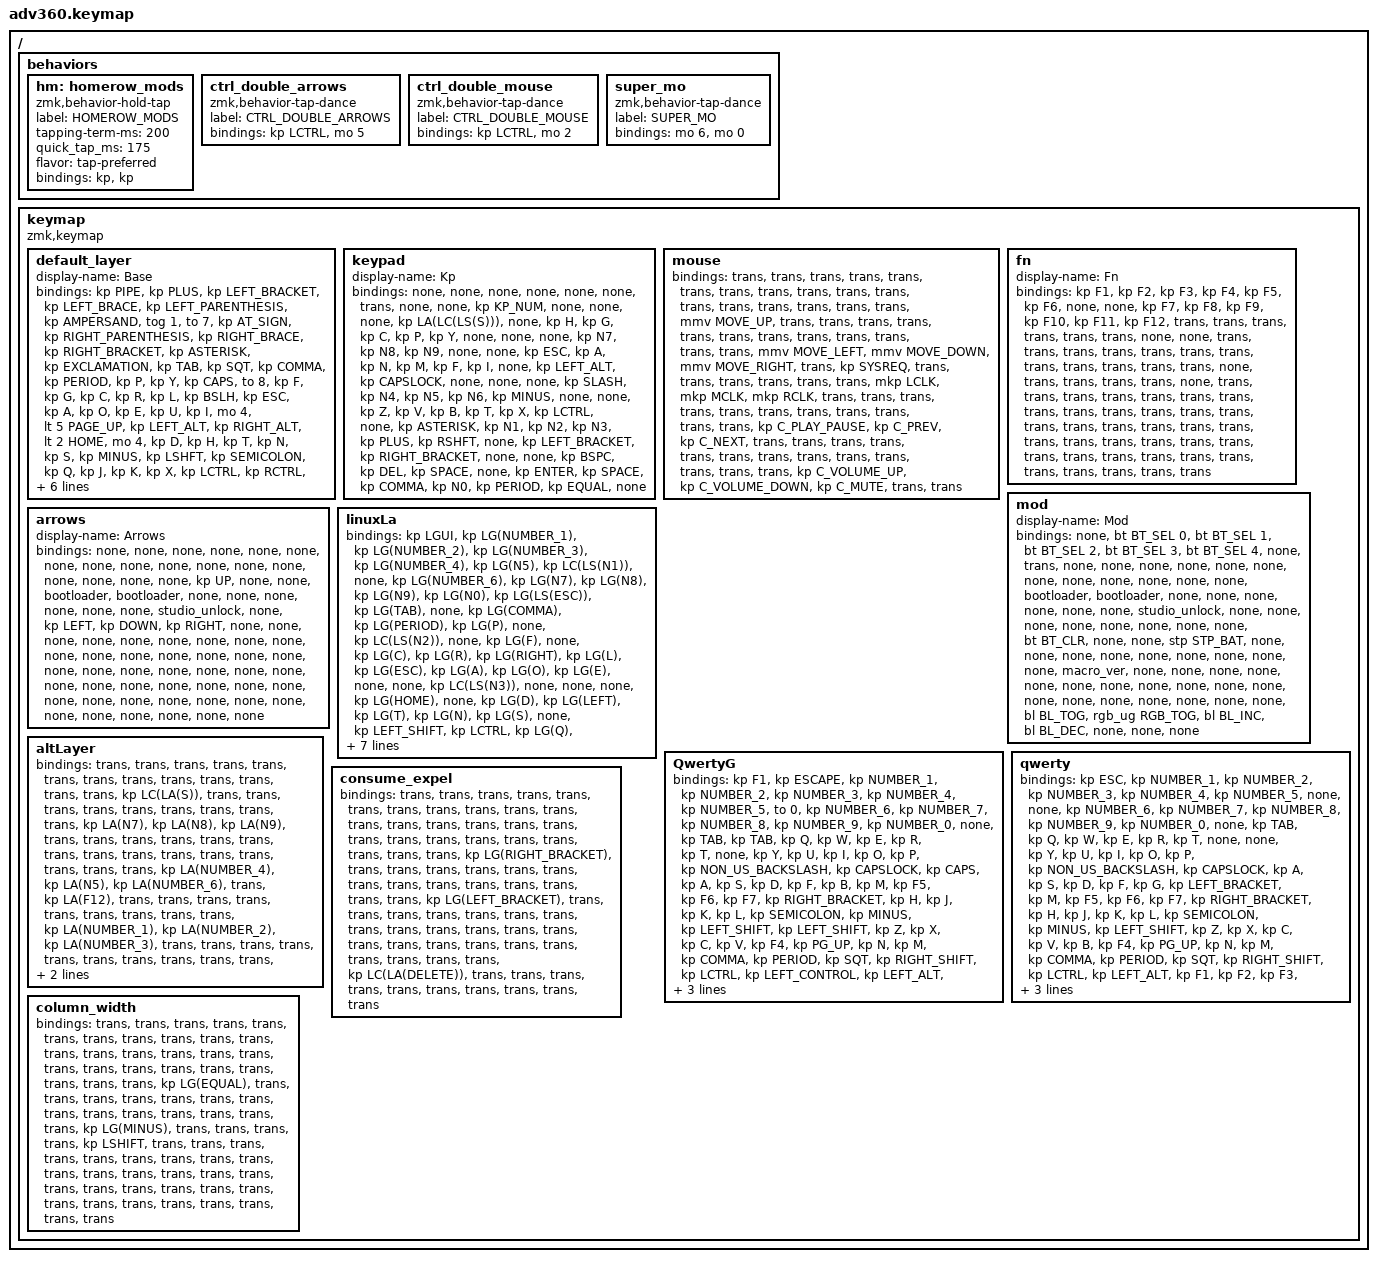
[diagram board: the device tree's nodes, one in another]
#include <dt-bindings/zmk/stp.h>
#include <behaviors.dtsi>
#include <dt-bindings/zmk/backlight.h>
#include <dt-bindings/zmk/bt.h>
#include <dt-bindings/zmk/keys.h>
#include <dt-bindings/zmk/pointing.h>
#include <dt-bindings/zmk/rgb.h>

#define ZMK_POINTING_DEFAULT_MOVE_VAL 1500

/ {
    behaviors {
        #include "macros.dtsi"
      #include "version.dtsi"

        hm: homerow_mods {
            compatible = "zmk,behavior-hold-tap";
            label = "HOMEROW_MODS";
            #binding-cells = <2>;
            tapping-term-ms = <200>;
            quick_tap_ms = <175>;
            flavor = "tap-preferred";
            bindings = <&kp>, <&kp>;
        };

        ctrl_double_arrows: ctrl_double_arrows {
            compatible = "zmk,behavior-tap-dance";
            label = "CTRL_DOUBLE_ARROWS";
            #binding-cells = <0>;
            bindings = <&kp LCTRL>, <&mo 5>;
        };

        ctrl_double_mouse: ctrl_double_mouse {
            compatible = "zmk,behavior-tap-dance";
            label = "CTRL_DOUBLE_MOUSE";
            #binding-cells = <0>;
            bindings = <&kp LCTRL>, <&mo 2>;
        };

        super_mo: super_mo {
            compatible = "zmk,behavior-tap-dance";
            label = "SUPER_MO";
            #binding-cells = <0>;
            bindings = <&mo 6>, <&mo 0>;
        };
    };

    keymap {
        compatible = "zmk,keymap";

        default_layer {
            display-name = "Base";
            bindings = <
&kp PIPE   &kp PLUS       &kp LEFT_BRACKET  &kp LEFT_BRACE  &kp LEFT_PARENTHESIS  &kp AMPERSAND  &tog 1                                                                   &to 7      &kp AT_SIGN  &kp RIGHT_PARENTHESIS  &kp RIGHT_BRACE  &kp RIGHT_BRACKET  &kp ASTERISK  &kp EXCLAMATION
&kp TAB    &kp SQT        &kp COMMA         &kp PERIOD      &kp P                 &kp Y          &kp CAPS                                                                 &to 8      &kp F        &kp G                  &kp C            &kp R              &kp L         &kp BSLH
&kp ESC    &kp A          &kp O             &kp E           &kp U                 &kp I          &mo 4     &lt 5 PAGE_UP  &kp LEFT_ALT         &kp RIGHT_ALT  &lt 2 HOME  &mo 4      &kp D        &kp H                  &kp T            &kp N              &kp S         &kp MINUS
&kp LSHFT  &kp SEMICOLON  &kp Q             &kp J           &kp K                 &kp X                                   &kp LCTRL            &kp RCTRL                             &kp B        &kp M                  &kp W            &kp V              &kp Z         &kp RSHFT
&mo 3      &kp DOLLAR     &kp GRAVE         &kp TILDE       &lt 1 PERCENT                        &kp BSPC  &kp DEL        &lt 6 PAGE_DOWN      &lt 9 END      &kp ENTER   &kp SPACE               &kp HASH               &kp CARET        &kp SLASH          &kp EQUAL     &mo 3
            >;
        };

        keypad {
            display-name = "Kp";
            bindings = <
&none    &none             &none              &none  &none  &none  &trans                                                      &none      &none         &kp KP_NUM  &none   &none       &none      &kp LA(LC(LS(S)))
&none    &kp H             &kp G              &kp C  &kp P  &kp Y  &none                                                       &none      &none         &kp N7      &kp N8  &kp N9      &none      &none
&kp ESC  &kp A             &kp N              &kp M  &kp F  &kp I  &none     &kp LEFT_ALT  &kp CAPSLOCK      &none  &none      &none      &kp SLASH     &kp N4      &kp N5  &kp N6      &kp MINUS  &none
&none    &kp Z             &kp V              &kp B  &kp T  &kp X                          &kp LCTRL         &none                        &kp ASTERISK  &kp N1      &kp N2  &kp N3      &kp PLUS   &kp RSHFT
&none    &kp LEFT_BRACKET  &kp RIGHT_BRACKET  &none  &none         &kp BSPC  &kp DEL       &kp SPACE         &none  &kp ENTER  &kp SPACE                &kp COMMA   &kp N0  &kp PERIOD  &kp EQUAL  &none
            >;
        };

        mouse {
            bindings = <
&trans  &trans  &trans          &trans          &trans           &trans  &trans                                          &trans  &trans  &trans            &trans             &trans      &trans  &trans
&trans  &trans  &trans          &mmv MOVE_UP    &trans           &trans  &trans                                          &trans  &trans  &trans            &trans             &trans      &trans  &trans
&trans  &trans  &mmv MOVE_LEFT  &mmv MOVE_DOWN  &mmv MOVE_RIGHT  &trans  &kp SYSREQ  &trans  &trans      &trans  &trans  &trans  &trans  &mkp LCLK         &mkp MCLK          &mkp RCLK   &trans  &trans
&trans  &trans  &trans          &trans          &trans           &trans                      &trans      &trans                  &trans  &kp C_PLAY_PAUSE  &kp C_PREV         &kp C_NEXT  &trans  &trans
&trans  &trans  &trans          &trans          &trans                   &trans      &trans  &trans      &trans  &trans  &trans          &kp C_VOLUME_UP   &kp C_VOLUME_DOWN  &kp C_MUTE  &trans  &trans
            >;
        };

        fn {
            display-name = "Fn";
            bindings = <
&kp F1  &kp F2  &kp F3  &kp F4  &kp F5  &kp F6  &none                                       &none   &kp F7  &kp F8  &kp F9  &kp F10  &kp F11  &kp F12
&trans  &trans  &trans  &trans  &trans  &trans  &none                                       &none   &trans  &trans  &trans  &trans   &trans   &trans
&trans  &trans  &trans  &trans  &trans  &trans  &none   &trans  &trans      &trans  &trans  &none   &trans  &trans  &trans  &trans   &trans   &trans
&trans  &trans  &trans  &trans  &trans  &trans                  &trans      &trans                  &trans  &trans  &trans  &trans   &trans   &trans
&trans  &trans  &trans  &trans  &trans          &trans  &trans  &trans      &trans  &trans  &trans          &trans  &trans  &trans   &trans   &trans
            >;
        };

        mod {
            display-name = "Mod";
            bindings = <
&none           &bt BT_SEL 0  &bt BT_SEL 1  &bt BT_SEL 2  &bt BT_SEL 3  &bt BT_SEL 4  &none                                                  &trans           &none         &none       &none       &none  &none  &none
&none           &none         &none         &none         &none         &none         &bootloader                                            &bootloader      &none         &none       &none       &none  &none  &none
&studio_unlock  &none         &none         &none         &none         &none         &none        &none  &none      &bt BT_CLR  &none       &none            &stp STP_BAT  &none       &none       &none  &none  &none
&none           &none         &none         &none         &macro_ver    &none                             &none      &none                                    &none         &none       &none       &none  &none  &none
&none           &none         &none         &none         &none                       &none        &none  &none      &none       &bl BL_TOG  &rgb_ug RGB_TOG                &bl BL_INC  &bl BL_DEC  &none  &none  &none
            >;
        };

        arrows {
            display-name = "Arrows";
            bindings = <
&none           &none  &none     &none     &none      &none  &none                                        &none        &none  &none  &none  &none  &none  &none
&none           &none  &none     &kp UP    &none      &none  &bootloader                                  &bootloader  &none  &none  &none  &none  &none  &none
&studio_unlock  &none  &kp LEFT  &kp DOWN  &kp RIGHT  &none  &none        &none  &none      &none  &none  &none        &none  &none  &none  &none  &none  &none
&none           &none  &none     &none     &none      &none                      &none      &none                      &none  &none  &none  &none  &none  &none
&none           &none  &none     &none     &none             &none        &none  &none      &none  &none  &none               &none  &none  &none  &none  &none
            >;
        };

        linuxLa {
            bindings = <
&kp LGUI        &kp LG(NUMBER_1)  &kp LG(NUMBER_2)  &kp LG(NUMBER_3)  &kp LG(NUMBER_4)  &kp LG(N5)  &kp LC(LS(N1))                                                &none          &kp LG(NUMBER_6)  &kp LG(N7)    &kp LG(N8)  &kp LG(N9)  &kp LG(N0)     &kp LG(LS(ESC))
&kp LG(TAB)     &none             &kp LG(COMMA)     &kp LG(PERIOD)    &kp LG(P)         &none       &kp LC(LS(N2))                                                &none          &kp LG(F)         &none         &kp LG(C)   &kp LG(R)   &kp LG(RIGHT)  &kp LG(L)
&kp LG(ESC)     &kp LG(A)         &kp LG(O)         &kp LG(E)         &none             &none       &kp LC(LS(N3))  &none  &none      &none        &kp LG(HOME)   &none          &kp LG(D)         &kp LG(LEFT)  &kp LG(T)   &kp LG(N)   &kp LG(S)      &none
&kp LEFT_SHIFT  &kp LCTRL         &kp LG(Q)         &kp LG(DOWN)      &kp LG(UP_ARROW)  &none                              &none      &none                                      &kp LG(B)         &kp LG(M)     &kp LG(W)   &kp LG(V)   &kp RCTRL      &kp RIGHT_SHIFT
&none           &kp LEFT_ALT      &none             &mo 10            &mo 11                        &none           &none  &none      &kp LG(END)  &kp LG(ENTER)  &kp LG(SPACE)                    &none         &none       &none       &kp RIGHT_ALT  &none
            >;
        };

        QwertyG {
            bindings = <
&kp F1          &kp ESCAPE        &kp NUMBER_1  &kp NUMBER_2  &kp NUMBER_3  &kp NUMBER_4  &kp NUMBER_5                                               &to 0              &kp NUMBER_6  &kp NUMBER_7  &kp NUMBER_8  &kp NUMBER_9  &kp NUMBER_0   &none
&kp TAB         &kp TAB           &kp Q         &kp W         &kp E         &kp R         &kp T                                                      &none              &kp Y         &kp U         &kp I         &kp O         &kp P          &kp NON_US_BACKSLASH
&kp CAPSLOCK    &kp CAPS          &kp A         &kp S         &kp D         &kp F         &kp B         &kp M  &kp F5      &kp F6         &kp F7     &kp RIGHT_BRACKET  &kp H         &kp J         &kp K         &kp L         &kp SEMICOLON  &kp MINUS
&kp LEFT_SHIFT  &kp LEFT_SHIFT    &kp Z         &kp X         &kp C         &kp V                              &kp F4      &kp PG_UP                                    &kp N         &kp M         &kp COMMA     &kp PERIOD    &kp SQT        &kp RIGHT_SHIFT
&kp LCTRL       &kp LEFT_CONTROL  &kp LEFT_ALT  &kp F2        &kp F3                      &kp SPACE     &kp R  &kp G       &kp PAGE_DOWN  &kp ENTER  &trans                           &kp F8        &kp F9        &kp F10       &kp F11        &kp F12
            >;
        };

        qwerty {
            bindings = <
&kp ESC         &kp NUMBER_1  &kp NUMBER_2  &kp NUMBER_3  &kp NUMBER_4  &kp NUMBER_5  &none                                                          &none              &kp NUMBER_6  &kp NUMBER_7  &kp NUMBER_8  &kp NUMBER_9  &kp NUMBER_0   &none
&kp TAB         &kp Q         &kp W         &kp E         &kp R         &kp T         &none                                                          &none              &kp Y         &kp U         &kp I         &kp O         &kp P          &kp NON_US_BACKSLASH
&kp CAPSLOCK    &kp A         &kp S         &kp D         &kp F         &kp G         &kp LEFT_BRACKET  &kp M  &kp F5      &kp F6         &kp F7     &kp RIGHT_BRACKET  &kp H         &kp J         &kp K         &kp L         &kp SEMICOLON  &kp MINUS
&kp LEFT_SHIFT  &kp Z         &kp X         &kp C         &kp V         &kp B                                  &kp F4      &kp PG_UP                                    &kp N         &kp M         &kp COMMA     &kp PERIOD    &kp SQT        &kp RIGHT_SHIFT
&kp LCTRL       &kp LEFT_ALT  &kp F1        &kp F2        &kp F3                      &kp SPACE         &kp R  &kp G       &kp PAGE_DOWN  &kp ENTER  &trans                           &kp F8        &kp F9        &kp F10       &kp F11        &kp F12
            >;
        };

        altLayer {
            bindings = <
&trans  &trans  &trans  &trans  &trans  &trans  &trans                                      &trans  &trans  &trans            &trans            &trans            &trans  &kp LC(LA(S))
&trans  &trans  &trans  &trans  &trans  &trans  &trans                                      &trans  &trans  &kp LA(N7)        &kp LA(N8)        &kp LA(N9)        &trans  &trans
&trans  &trans  &trans  &trans  &trans  &trans  &trans  &trans  &trans      &trans  &trans  &trans  &trans  &kp LA(NUMBER_4)  &kp LA(N5)        &kp LA(NUMBER_6)  &trans  &kp LA(F12)
&trans  &trans  &trans  &trans  &trans  &trans                  &trans      &trans                  &trans  &kp LA(NUMBER_1)  &kp LA(NUMBER_2)  &kp LA(NUMBER_3)  &trans  &trans
&trans  &trans  &trans  &trans  &trans          &trans  &trans  &trans      &trans  &trans  &trans          &trans            &trans            &trans            &trans  &trans
            >;
        };

        consume_expel {
            bindings = <
&trans  &trans  &trans  &trans  &trans  &trans  &trans                                                  &trans  &trans  &trans                &trans  &trans  &trans                 &trans
&trans  &trans  &trans  &trans  &trans  &trans  &trans                                                  &trans  &trans  &trans                &trans  &trans  &kp LG(RIGHT_BRACKET)  &trans
&trans  &trans  &trans  &trans  &trans  &trans  &trans              &trans  &trans      &trans  &trans  &trans  &trans  &kp LG(LEFT_BRACKET)  &trans  &trans  &trans                 &trans
&trans  &trans  &trans  &trans  &trans  &trans                              &trans      &trans                  &trans  &trans                &trans  &trans  &trans                 &trans
&trans  &trans  &trans  &trans  &trans          &kp LC(LA(DELETE))  &trans  &trans      &trans  &trans  &trans          &trans                &trans  &trans  &trans                 &trans
            >;
        };

        column_width {
            bindings = <
&trans      &trans  &trans  &trans  &trans  &trans  &trans                                      &trans  &trans  &trans         &trans  &trans  &trans         &trans
&trans      &trans  &trans  &trans  &trans  &trans  &trans                                      &trans  &trans  &trans         &trans  &trans  &kp LG(EQUAL)  &trans
&trans      &trans  &trans  &trans  &trans  &trans  &trans  &trans  &trans      &trans  &trans  &trans  &trans  &kp LG(MINUS)  &trans  &trans  &trans         &trans
&kp LSHIFT  &trans  &trans  &trans  &trans  &trans                  &trans      &trans                  &trans  &trans         &trans  &trans  &trans         &trans
&trans      &trans  &trans  &trans  &trans          &trans  &trans  &trans      &trans  &trans  &trans          &trans         &trans  &trans  &trans         &trans
            >;
        };
    };
};
